# STM32MP157x register map
File version: 1.7
Registers are 32-bit, read-write, reset 0x0 unless marked. A register's access mark holds for its fields unless they carry their own. Offsets are from the block's base; [hi:lo] are bit positions; {n}, {i} and the like mark numbered series.

## IPCC
Base 0x4C001000
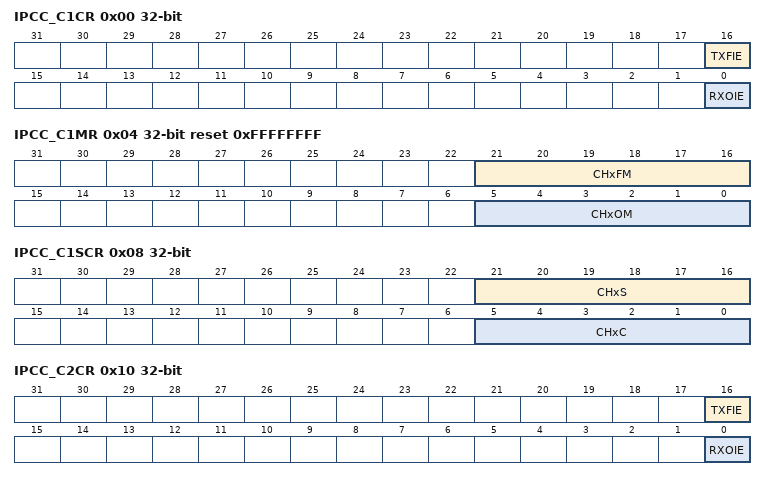
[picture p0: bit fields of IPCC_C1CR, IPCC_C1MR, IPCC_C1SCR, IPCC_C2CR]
0x00 IPCC_C1CR — IPCC Processor 1 control register
  [16] TXFIE, [0] RXOIE
0x04 IPCC_C1MR reset 0xFFFFFFFF — IPCC Processor 1 mask register
  [21:16] CHxFM, [5:0] CHxOM
0x08 IPCC_C1SCR — Reading this register will always return 0x0000 0000.
  [21:16] CHxS, [5:0] CHxC
0x0C IPCC_C1TOC2SR ro — IPCC processor 1 to processor 2 status register
  [5:0] CHxF
0x10 IPCC_C2CR — IPCC Processor 2 control register
  [16] TXFIE, [0] RXOIE
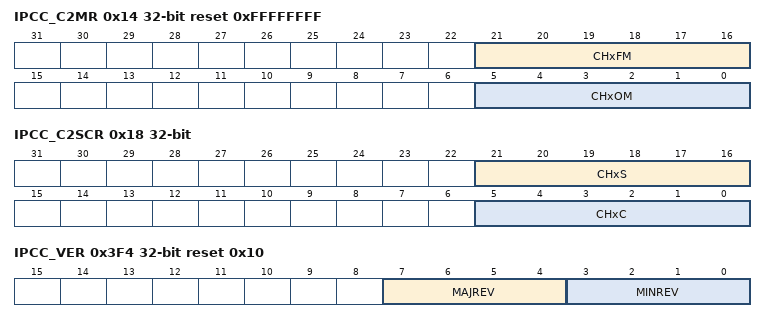
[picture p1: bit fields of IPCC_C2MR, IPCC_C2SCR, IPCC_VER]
0x14 IPCC_C2MR reset 0xFFFFFFFF — IPCC Processor 2 mask register
  [21:16] CHxFM, [5:0] CHxOM
0x18 IPCC_C2SCR — Reading this register will always return 0x0000 0000.
  [21:16] CHxS, [5:0] CHxC
0x1C IPCC_C2TOC1SR ro — IPCC processor 2 to processor 1 status register
  [5:0] CHxF
0x3F0 IPCC_HWCFGR ro reset 0x2 — IPCC Hardware configuration register
  [7:0] CHANNELS
0x3F4 IPCC_VER ro reset 0x10 — IPCC IP Version register
  [7:4] MAJREV, [3:0] MINREV
0x3F8 IPCC_ID ro reset 0x100071 — IPCC IP Identification register
  [31:0] IPID
0x3FC IPCC_SID ro reset 0xA3C5DD01 — IPCC Size ID register

## IWDG1
Base 0x5C003000
Same registers: IWDG2 0x5A002000
0x00 IWDG_KR wo — Key register
  [15:0] KEY
0x04 IWDG_PR reset 0x7 — Prescaler register
  [2:0] PR
0x08 IWDG_RLR reset 0xFFF — Reload register
  [11:0] RL
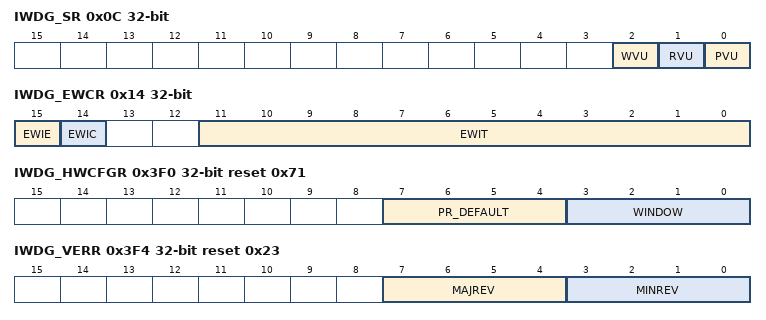
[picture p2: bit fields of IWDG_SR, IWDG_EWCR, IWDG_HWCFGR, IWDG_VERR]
0x0C IWDG_SR ro — Status register
  [2] WVU, [1] RVU, [0] PVU
0x10 IWDG_WINR reset 0xFFF — Window register
  [11:0] WIN
0x14 IWDG_EWCR — IWDG early wake-up interrupt register
  [15] EWIE, [14] EWIC, [11:0] EWIT
0x3F0 IWDG_HWCFGR ro reset 0x71 — IWDG hardware configuration register
  [7:4] PR_DEFAULT, [3:0] WINDOW
0x3F4 IWDG_VERR ro reset 0x23 — IWDG version register
  [7:4] MAJREV, [3:0] MINREV
0x3F8 IWDG_IDR ro reset 0x120041 — IWDG identification register
  [31:0] ID
0x3FC IWDG_SIDR ro reset 0xA3C5DD01 — IWDG size identification register
  [31:0] SID

## LPTIM1
Base 0x40009000
Same registers: LPTIM2 0x50021000, LPTIM3 0x50022000, LPTIM4 0x50023000, LPTIM5 0x50024000
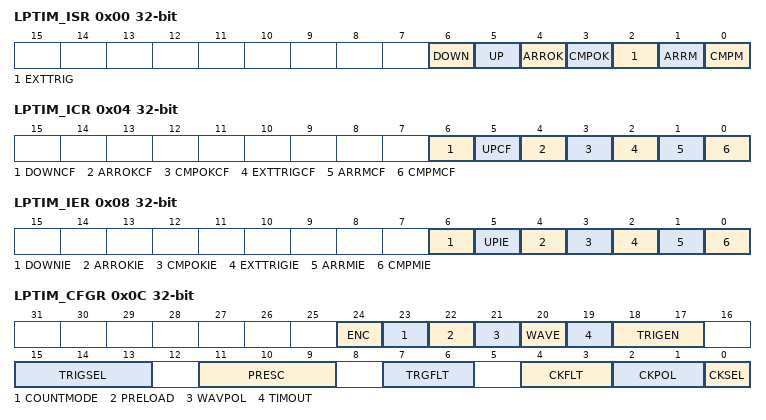
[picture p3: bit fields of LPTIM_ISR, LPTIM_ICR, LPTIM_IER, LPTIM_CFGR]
0x00 LPTIM_ISR ro — LPTIM interrupt and status register
  [6] DOWN, [5] UP, [4] ARROK, [3] CMPOK, [2] EXTTRIG, [1] ARRM, [0] CMPM
0x04 LPTIM_ICR wo — LPTIM interrupt clear register
  [6] DOWNCF, [5] UPCF, [4] ARROKCF, [3] CMPOKCF, [2] EXTTRIGCF, [1] ARRMCF, [0] CMPMCF
0x08 LPTIM_IER — LPTIM interrupt enable register
  [6] DOWNIE, [5] UPIE, [4] ARROKIE, [3] CMPOKIE, [2] EXTTRIGIE, [1] ARRMIE, [0] CMPMIE
0x0C LPTIM_CFGR — LPTIM configuration register
  [24] ENC, [23] COUNTMODE, [22] PRELOAD, [21] WAVPOL, [20] WAVE, [19] TIMOUT, [18:17] TRIGEN, [15:13] TRIGSEL, [11:9] PRESC, [7:6] TRGFLT, [4:3] CKFLT, [2:1] CKPOL, [0] CKSEL
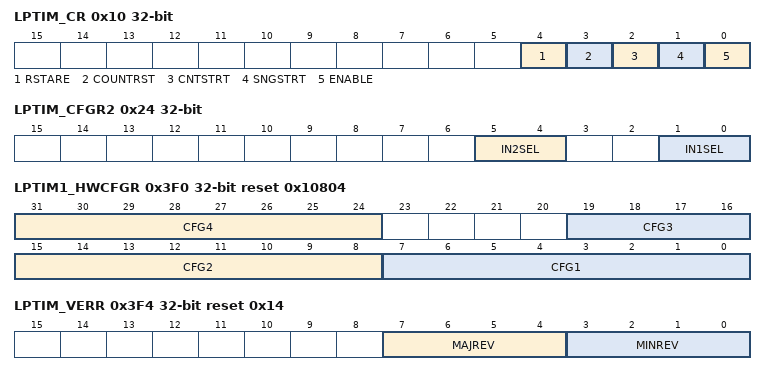
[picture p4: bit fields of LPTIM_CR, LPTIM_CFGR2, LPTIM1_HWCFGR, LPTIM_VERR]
0x10 LPTIM_CR — LPTIM control register
  [4] RSTARE, [3] COUNTRST, [2] CNTSTRT, [1] SNGSTRT, [0] ENABLE
0x14 LPTIM_CMP — LPTIM compare register
  [15:0] CMP
0x18 LPTIM_ARR reset 0x1 — LPTIM autoreload register
  [15:0] ARR
0x1C LPTIM_CNT ro — LPTIM counter register
  [15:0] CNT
0x24 LPTIM_CFGR2 — LPTIM configuration register 2
  [5:4] IN2SEL, [1:0] IN1SEL
0x3F0 LPTIM1_HWCFGR ro reset 0x10804 — LPTIM 1 peripheral hardware configuration register
  [31:24] CFG4, [19:16] CFG3, [15:8] CFG2, [7:0] CFG1
0x3F4 LPTIM_VERR ro reset 0x14 — LPTIM peripheral version identification register
  [7:4] MAJREV, [3:0] MINREV
0x3F8 LPTIM_PIDR ro reset 0x120011 — LPTIM peripheral type identification register
  [31:0] P_ID
0x3FC LPTIM_SIDR ro reset 0xA3C5DD01 — LPTIM registers map size identification register
  [31:0] S_ID

## MDIOS
Base 0x4001C000
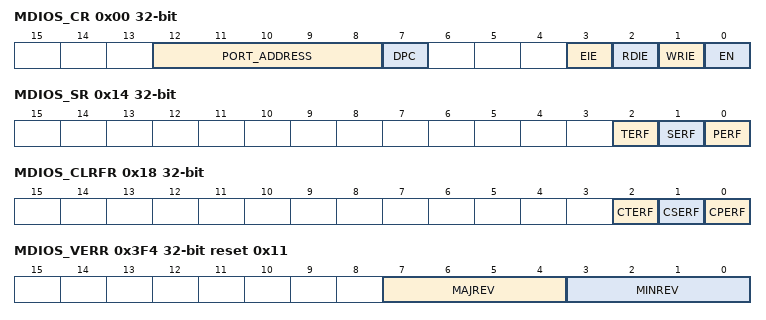
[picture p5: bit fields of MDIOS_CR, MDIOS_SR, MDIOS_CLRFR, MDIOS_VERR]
0x00 MDIOS_CR — MDIOS configuration register
  [12:8] PORT_ADDRESS, [7] DPC, [3] EIE, [2] RDIE, [1] WRIE, [0] EN
0x04 MDIOS_WRFR ro — MDIOS write flag register
  [31:0] WRF
0x08 MDIOS_CWRFR — MDIOS clear write flag register
  [31:0] CWRF
0x0C MDIOS_RDFR ro — MDIOS read flag register
  [31:0] RDF
0x10 MDIOS_CRDFR — MDIOS clear read flag register
  [31:0] CRDF
0x14 MDIOS_SR ro — MDIOS status register
  [2] TERF, [1] SERF, [0] PERF
0x18 MDIOS_CLRFR — MDIOS clear flag register
  [2] CTERF, [1] CSERF, [0] CPERF
{0x100+4i} MDIOS_DINR{i} ro (i=0..31) — MDIOS input data register
  [15:0] DIN
0x180 MDIOS_DOUTR0 ro — MDIOS input data register
  [15:0] DOUT
0x184 MDIOS_DOUTR1 ro — MDIOS input data register
  [15:0] DOUT
{0x180+4i} MDIOS_DOUTR{i} ro (i=2..31) — MDIOS output data register
  [15:0] DOUT
0x3F0 MDIOS_HWCFGR ro reset 0x20 — MDIOS HW configuration register
  [7:0] NBREG
0x3F4 MDIOS_VERR ro reset 0x11 — MDIOS version register
  [7:4] MAJREV, [3:0] MINREV
0x3F8 MDIOS_IPIDR ro reset 0x180001 — MDIOS identification register
  [31:0] ID
0x3FC MDIOS_SIDR ro reset 0xA3C5DD01 — MDIOS size identification register
  [31:0] SID

## Notices in the file
Copyright (c) 2024 STMicroelectronics.
SPDX-License-Identifier: Apache-2.0
Licensed under the Apache License, Version 2.0 (the "License");
you may not use this file except in compliance with the License.
You may obtain a copy of the License at
http://www.apache.org/licenses/LICENSE-2.0
Unless required by applicable law or agreed to in writing, software
distributed under the License is distributed on an "AS IS" BASIS,
WITHOUT WARRANTIES OR CONDITIONS OF ANY KIND, either express or implied.
See the License for the specific language governing permissions and
limitations under the License.
